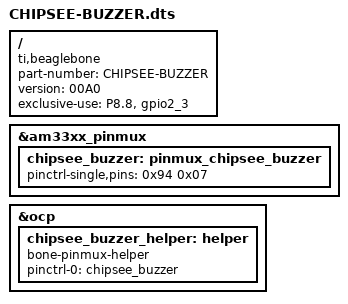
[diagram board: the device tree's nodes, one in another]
/*
*	CHIPSEE BeagleBone Black Expansion V1
*	Device Tree: Buzzer
*	Date:        04.11.2013
*	Author:      Oliver Schlag <oliver.schlag@gmail.com>
*/
/dts-v1/;
/plugin/;

/ {
        compatible = "ti,beaglebone", "ti,beaglebone-black";

        /* identification */
        part-number = "CHIPSEE-BUZZER";
        version = "00A0";

        /* state the resources this cape uses */
        exclusive-use = "P8.8", "gpio2_3";

        fragment@0 {
                target = <&am33xx_pinmux>;
                __overlay__ {
                        chipsee_buzzer: pinmux_chipsee_buzzer {
                                pinctrl-single,pins = <
                                        0x94 0x07 /* P8_8 OUTPUT */
                                >;
                        };
                };
        };

        fragment@1 {
                target = <&ocp>;
                __overlay__ {
                        chipsee_buzzer_helper: helper {
                                compatible = "bone-pinmux-helper";
                                pinctrl-names = "default";
                                pinctrl-0 = <&chipsee_buzzer>;
                                status = "okay";
                        };
                };
        };

};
